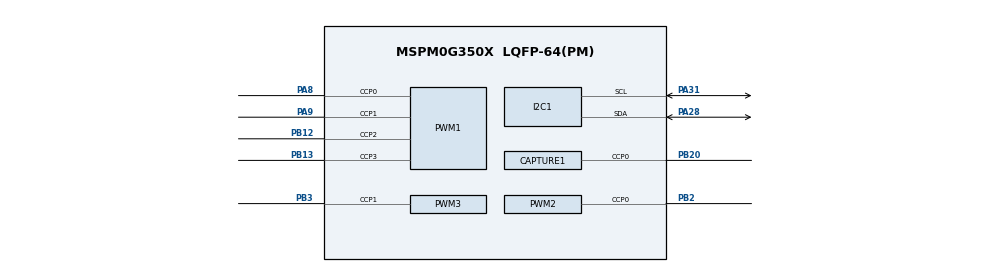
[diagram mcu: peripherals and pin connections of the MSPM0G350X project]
/**
 * @cliArgs --device "MSPM0G350X" --part "Default" --package "LQFP-64(PM)" --product "mspm0_sdk@2.02.00.05"
 * @versions {"tool":"1.21.1+3772"}
 */

/**
 * Import the modules used in this configuration.
 */
const CAPTURE  = scripting.addModule("/ti/driverlib/CAPTURE", {}, false);
const CAPTURE1 = CAPTURE.addInstance();
const GPIO     = scripting.addModule("/ti/driverlib/GPIO", {}, false);
const GPIO1    = GPIO.addInstance();
const GPIO2    = GPIO.addInstance();
const GPIO3    = GPIO.addInstance();
const GPIO4    = GPIO.addInstance();
const GPIO5    = GPIO.addInstance();
const GPIO6    = GPIO.addInstance();
const GPIO7    = GPIO.addInstance();
const GPIO8    = GPIO.addInstance();
const GPIO9    = GPIO.addInstance();
const GPIO10   = GPIO.addInstance();
const GPIO11   = GPIO.addInstance();
const GPIO12   = GPIO.addInstance();
const GPIO13   = GPIO.addInstance();
const GPIO14   = GPIO.addInstance();
const GPIO15   = GPIO.addInstance();
const GPIO16   = GPIO.addInstance();
const I2C      = scripting.addModule("/ti/driverlib/I2C", {}, false);
const I2C1     = I2C.addInstance();
const PWM      = scripting.addModule("/ti/driverlib/PWM", {}, false);
const PWM1     = PWM.addInstance();
const PWM2     = PWM.addInstance();
const PWM3     = PWM.addInstance();
const SYSCTL   = scripting.addModule("/ti/driverlib/SYSCTL");
const TIMER    = scripting.addModule("/ti/driverlib/TIMER", {}, false);
const TIMER1   = TIMER.addInstance();
const UART     = scripting.addModule("/ti/driverlib/UART", {}, false);
const UART1    = UART.addInstance();

/**
 * Write custom configuration values to the imported modules.
 */
CAPTURE1.$name                              = "ULTRASONIC_TIMER";
CAPTURE1.timerClkDiv                        = 8;
CAPTURE1.timerPeriod                        = "40ms";
CAPTURE1.peripheral.$assign                 = "TIMG12";
CAPTURE1.peripheral.ccp0Pin.$assign         = "PB20";
CAPTURE1.ccp0PinConfig.hideOutputInversion  = scripting.forceWrite(false);
CAPTURE1.ccp0PinConfig.onlyInternalResistor = scripting.forceWrite(false);
CAPTURE1.ccp0PinConfig.passedPeripheralType = scripting.forceWrite("Digital");
CAPTURE1.ccp0PinConfig.$name                = "ti_driverlib_gpio_GPIOPinGeneric8";

const Board = scripting.addModule("/ti/driverlib/Board", {}, false);

GPIO1.$name                          = "MOTORA_DIR";
GPIO1.associatedPins.create(2);
GPIO1.associatedPins[0].$name        = "MOTA_DIR1";
GPIO1.associatedPins[0].assignedPort = "PORTB";
GPIO1.associatedPins[0].assignedPin  = "15";
GPIO1.associatedPins[1].$name        = "MOTA_DIR2";
GPIO1.associatedPins[1].assignedPort = "PORTB";
GPIO1.associatedPins[1].assignedPin  = "16";

GPIO2.$name                          = "MOTORB_DIR";
GPIO2.associatedPins.create(2);
GPIO2.associatedPins[0].$name        = "MOTB_DIR1";
GPIO2.associatedPins[0].assignedPort = "PORTB";
GPIO2.associatedPins[0].assignedPin  = "5";
GPIO2.associatedPins[1].$name        = "MOTB_DIR2";
GPIO2.associatedPins[1].assignedPort = "PORTB";
GPIO2.associatedPins[1].assignedPin  = "4";

GPIO3.$name                          = "MOTORC_DIR";
GPIO3.associatedPins.create(2);
GPIO3.associatedPins[0].$name        = "MOTC_DIR1";
GPIO3.associatedPins[0].assignedPort = "PORTB";
GPIO3.associatedPins[0].assignedPin  = "9";
GPIO3.associatedPins[1].$name        = "MOTC_DIR2";
GPIO3.associatedPins[1].assignedPort = "PORTB";
GPIO3.associatedPins[1].assignedPin  = "7";

GPIO4.$name                          = "MOTORD_DIR";
GPIO4.associatedPins.create(2);
GPIO4.associatedPins[0].$name        = "MOTD_DIR1";
GPIO4.associatedPins[0].assignedPort = "PORTB";
GPIO4.associatedPins[0].assignedPin  = "26";
GPIO4.associatedPins[1].$name        = "MOTD_DIR2";
GPIO4.associatedPins[1].assignedPort = "PORTA";
GPIO4.associatedPins[1].assignedPin  = "13";

GPIO5.$name                          = "ENCA";
GPIO5.associatedPins.create(2);
GPIO5.associatedPins[0].$name        = "ENCA_A";
GPIO5.associatedPins[0].direction    = "INPUT";
GPIO5.associatedPins[0].assignedPort = "PORTB";
GPIO5.associatedPins[0].assignedPin  = "10";
GPIO5.associatedPins[0].interruptEn  = true;
GPIO5.associatedPins[0].polarity     = "FALL";
GPIO5.associatedPins[1].$name        = "ENCA_B";
GPIO5.associatedPins[1].direction    = "INPUT";
GPIO5.associatedPins[1].assignedPort = "PORTB";
GPIO5.associatedPins[1].assignedPin  = "11";
GPIO5.associatedPins[1].interruptEn  = true;
GPIO5.associatedPins[1].polarity     = "FALL";

GPIO6.$name                          = "ENCB";
GPIO6.associatedPins.create(2);
GPIO6.associatedPins[0].direction    = "INPUT";
GPIO6.associatedPins[0].$name        = "ENCB_A";
GPIO6.associatedPins[0].assignedPort = "PORTA";
GPIO6.associatedPins[0].assignedPin  = "29";
GPIO6.associatedPins[0].interruptEn  = true;
GPIO6.associatedPins[0].polarity     = "FALL";
GPIO6.associatedPins[1].direction    = "INPUT";
GPIO6.associatedPins[1].assignedPort = "PORTB";
GPIO6.associatedPins[1].$name        = "ENCB_b";
GPIO6.associatedPins[1].assignedPin  = "27";
GPIO6.associatedPins[1].interruptEn  = true;
GPIO6.associatedPins[1].polarity     = "FALL";

GPIO7.$name                          = "ENCC";
GPIO7.associatedPins.create(2);
GPIO7.associatedPins[0].direction    = "INPUT";
GPIO7.associatedPins[0].$name        = "ENCC_A";
GPIO7.associatedPins[0].assignedPort = "PORTA";
GPIO7.associatedPins[0].assignedPin  = "26";
GPIO7.associatedPins[0].interruptEn  = true;
GPIO7.associatedPins[0].polarity     = "FALL";
GPIO7.associatedPins[1].direction    = "INPUT";
GPIO7.associatedPins[1].$name        = "ENCC_B";
GPIO7.associatedPins[1].assignedPort = "PORTA";
GPIO7.associatedPins[1].assignedPin  = "27";
GPIO7.associatedPins[1].interruptEn  = true;
GPIO7.associatedPins[1].polarity     = "FALL";

GPIO8.$name                          = "ENCD";
GPIO8.associatedPins.create(2);
GPIO8.associatedPins[0].direction    = "INPUT";
GPIO8.associatedPins[0].assignedPort = "PORTB";
GPIO8.associatedPins[0].$name        = "ENCD_A";
GPIO8.associatedPins[0].assignedPin  = "21";
GPIO8.associatedPins[0].interruptEn  = true;
GPIO8.associatedPins[0].polarity     = "FALL";
GPIO8.associatedPins[1].direction    = "INPUT";
GPIO8.associatedPins[1].assignedPort = "PORTB";
GPIO8.associatedPins[1].$name        = "ENCD_B";
GPIO8.associatedPins[1].assignedPin  = "19";
GPIO8.associatedPins[1].interruptEn  = true;
GPIO8.associatedPins[1].polarity     = "FALL";

GPIO9.$name                          = "PTZ_DIR";
GPIO9.associatedPins.create(2);
GPIO9.associatedPins[0].$name        = "PTZ1_DIR";
GPIO9.associatedPins[0].assignedPort = "PORTA";
GPIO9.associatedPins[0].assignedPin  = "12";
GPIO9.associatedPins[1].$name        = "PTZ2_DIR";
GPIO9.associatedPins[1].assignedPort = "PORTB";
GPIO9.associatedPins[1].assignedPin  = "23";

GPIO10.$name                          = "ULTRASONIC";
GPIO10.associatedPins[0].$name        = "TRIG";
GPIO10.associatedPins[0].assignedPort = "PORTB";
GPIO10.associatedPins[0].assignedPin  = "25";

GPIO11.$name                          = "GRAY";
GPIO11.associatedPins.create(8);
GPIO11.associatedPins[0].$name        = "OUT1";
GPIO11.associatedPins[0].direction    = "INPUT";
GPIO11.associatedPins[0].assignedPort = "PORTA";
GPIO11.associatedPins[0].assignedPin  = "24";
GPIO11.associatedPins[1].$name        = "OUT2";
GPIO11.associatedPins[1].direction    = "INPUT";
GPIO11.associatedPins[1].assignedPort = "PORTA";
GPIO11.associatedPins[1].assignedPin  = "25";
GPIO11.associatedPins[2].$name        = "OUT3";
GPIO11.associatedPins[2].direction    = "INPUT";
GPIO11.associatedPins[2].assignedPort = "PORTB";
GPIO11.associatedPins[2].assignedPin  = "24";
GPIO11.associatedPins[3].$name        = "OUT4";
GPIO11.associatedPins[3].direction    = "INPUT";
GPIO11.associatedPins[3].assignedPort = "PORTA";
GPIO11.associatedPins[3].assignedPin  = "22";
GPIO11.associatedPins[4].$name        = "OUT5";
GPIO11.associatedPins[4].direction    = "INPUT";
GPIO11.associatedPins[4].assignedPort = "PORTA";
GPIO11.associatedPins[4].assignedPin  = "14";
GPIO11.associatedPins[5].$name        = "OUT6";
GPIO11.associatedPins[5].direction    = "INPUT";
GPIO11.associatedPins[5].assignedPort = "PORTA";
GPIO11.associatedPins[5].assignedPin  = "17";
GPIO11.associatedPins[6].$name        = "OUT7";
GPIO11.associatedPins[6].direction    = "INPUT";
GPIO11.associatedPins[6].assignedPort = "PORTB";
GPIO11.associatedPins[6].assignedPin  = "17";
GPIO11.associatedPins[7].$name        = "OUT8";
GPIO11.associatedPins[7].direction    = "INPUT";
GPIO11.associatedPins[7].assignedPort = "PORTB";
GPIO11.associatedPins[7].assignedPin  = "18";

GPIO12.$name                          = "KEY";
GPIO12.associatedPins.create(2);
GPIO12.associatedPins[0].$name        = "KEY1";
GPIO12.associatedPins[0].direction    = "INPUT";
GPIO12.associatedPins[0].assignedPort = "PORTA";
GPIO12.associatedPins[0].assignedPin  = "0";
GPIO12.associatedPins[0].interruptEn  = true;
GPIO12.associatedPins[0].polarity     = "FALL";
GPIO12.associatedPins[1].$name        = "KEY2";
GPIO12.associatedPins[1].direction    = "INPUT";
GPIO12.associatedPins[1].assignedPort = "PORTA";
GPIO12.associatedPins[1].assignedPin  = "1";
GPIO12.associatedPins[1].interruptEn  = true;
GPIO12.associatedPins[1].polarity     = "FALL";

GPIO13.$name                          = "LED12";
GPIO13.associatedPins.create(2);
GPIO13.associatedPins[0].$name        = "LED1_PIN";
GPIO13.associatedPins[0].assignedPort = "PORTB";
GPIO13.associatedPins[0].assignedPin  = "22";
GPIO13.associatedPins[0].initialValue = "SET";
GPIO13.associatedPins[1].$name        = "LED2_PIN";
GPIO13.associatedPins[1].assignedPort = "PORTA";
GPIO13.associatedPins[1].assignedPin  = "30";
GPIO13.associatedPins[1].initialValue = "SET";

GPIO14.$name                          = "LED34";
GPIO14.associatedPins.create(2);
GPIO14.associatedPins[0].$name        = "LED3_PIN";
GPIO14.associatedPins[0].assignedPort = "PORTB";
GPIO14.associatedPins[0].assignedPin  = "0";
GPIO14.associatedPins[0].initialValue = "SET";
GPIO14.associatedPins[1].$name        = "LED4_PIN";
GPIO14.associatedPins[1].assignedPort = "PORTB";
GPIO14.associatedPins[1].assignedPin  = "1";
GPIO14.associatedPins[1].initialValue = "SET";

GPIO15.$name                          = "BEEP_GPIO";
GPIO15.associatedPins[0].$name        = "BEEP_PIN";
GPIO15.associatedPins[0].assignedPort = "PORTA";
GPIO15.associatedPins[0].assignedPin  = "7";

GPIO16.$name                          = "OLED";
GPIO16.associatedPins.create(2);
GPIO16.associatedPins[0].$name        = "OLED_SDA";
GPIO16.associatedPins[0].assignedPort = "PORTA";
GPIO16.associatedPins[0].assignedPin  = "15";
GPIO16.associatedPins[1].$name        = "OLED_SCL";
GPIO16.associatedPins[1].assignedPort = "PORTA";
GPIO16.associatedPins[1].assignedPin  = "16";

I2C1.$name                     = "I2C_0";
I2C1.peripheral.sdaPin.$assign = "PA28";
I2C1.peripheral.sclPin.$assign = "PA31";
I2C1.sdaPinConfig.$name        = "ti_driverlib_gpio_GPIOPinGeneric5";
I2C1.sclPinConfig.$name        = "ti_driverlib_gpio_GPIOPinGeneric7";

PWM1.$name                              = "MOTOR_PWM";
PWM1.clockDivider                       = 8;
PWM1.ccIndex                            = [0,1,2,3];
PWM1.timerStartTimer                    = true;
PWM1.clockPrescale                      = 4;
PWM1.peripheral.ccp0Pin.$assign         = "PA8";
PWM1.peripheral.ccp1Pin.$assign         = "PA9";
PWM1.peripheral.ccp2Pin.$assign         = "PB12";
PWM1.peripheral.ccp3Pin.$assign         = "PB13";
PWM1.PWM_CHANNEL_0.$name                = "ti_driverlib_pwm_PWMTimerCC0";
PWM1.PWM_CHANNEL_1.$name                = "ti_driverlib_pwm_PWMTimerCC1";
PWM1.ccp0PinConfig.direction            = scripting.forceWrite("OUTPUT");
PWM1.ccp0PinConfig.hideOutputInversion  = scripting.forceWrite(false);
PWM1.ccp0PinConfig.onlyInternalResistor = scripting.forceWrite(false);
PWM1.ccp0PinConfig.passedPeripheralType = scripting.forceWrite("Digital");
PWM1.ccp0PinConfig.$name                = "ti_driverlib_gpio_GPIOPinGeneric0";
PWM1.ccp1PinConfig.direction            = scripting.forceWrite("OUTPUT");
PWM1.ccp1PinConfig.hideOutputInversion  = scripting.forceWrite(false);
PWM1.ccp1PinConfig.onlyInternalResistor = scripting.forceWrite(false);
PWM1.ccp1PinConfig.passedPeripheralType = scripting.forceWrite("Digital");
PWM1.ccp1PinConfig.$name                = "ti_driverlib_gpio_GPIOPinGeneric1";
PWM1.PWM_CHANNEL_2.$name                = "ti_driverlib_pwm_PWMTimerCC2";
PWM1.PWM_CHANNEL_3.$name                = "ti_driverlib_pwm_PWMTimerCC3";
PWM1.ccp2PinConfig.$name                = "ti_driverlib_gpio_GPIOPinGeneric2";
PWM1.ccp3PinConfig.$name                = "ti_driverlib_gpio_GPIOPinGeneric3";

PWM2.$name                              = "PTZ1_PWM";
PWM2.clockDivider                       = 8;
PWM2.clockPrescale                      = 100;
PWM2.ccIndex                            = [0];
PWM2.peripheral.ccp0Pin.$assign         = "PB2";
PWM2.PWM_CHANNEL_0.$name                = "ti_driverlib_pwm_PWMTimerCC4";
PWM2.PWM_CHANNEL_0.dutyCycle            = 50;
PWM2.ccp0PinConfig.direction            = scripting.forceWrite("OUTPUT");
PWM2.ccp0PinConfig.hideOutputInversion  = scripting.forceWrite(false);
PWM2.ccp0PinConfig.onlyInternalResistor = scripting.forceWrite(false);
PWM2.ccp0PinConfig.passedPeripheralType = scripting.forceWrite("Digital");
PWM2.ccp0PinConfig.$name                = "ti_driverlib_gpio_GPIOPinGeneric4";

PWM3.$name                              = "PTZ2_PWM";
PWM3.clockDivider                       = 8;
PWM3.clockPrescale                      = 100;
PWM3.ccIndex                            = [1];
PWM3.peripheral.$assign                 = "TIMG6";
PWM3.peripheral.ccp1Pin.$assign         = "PB3";
PWM3.ccp1PinConfig.direction            = scripting.forceWrite("OUTPUT");
PWM3.ccp1PinConfig.hideOutputInversion  = scripting.forceWrite(false);
PWM3.ccp1PinConfig.onlyInternalResistor = scripting.forceWrite(false);
PWM3.ccp1PinConfig.passedPeripheralType = scripting.forceWrite("Digital");
PWM3.ccp1PinConfig.$name                = "ti_driverlib_gpio_GPIOPinGeneric6";
PWM3.PWM_CHANNEL_1.$name                = "ti_driverlib_pwm_PWMTimerCC5";
PWM3.PWM_CHANNEL_1.dutyCycle            = 50;

SYSCTL.forceDefaultClkConfig = true;

TIMER1.$name              = "PID_TIMER";
TIMER1.timerClkDiv        = 8;
TIMER1.interrupts         = ["ZERO"];
TIMER1.timerClkPrescale   = 4;
TIMER1.timerPeriod        = "10ms";
TIMER1.peripheral.$assign = "TIMG7";

UART1.$name                            = "UART0";
UART1.enabledDMARXTriggers             = "DL_UART_DMA_INTERRUPT_RX";
UART1.enabledDMATXTriggers             = "DL_UART_DMA_INTERRUPT_TX";
UART1.enabledInterrupts                = ["DMA_DONE_RX","DMA_DONE_TX","RX_TIMEOUT_ERROR"];
UART1.txPinConfig.$name                = "ti_driverlib_gpio_GPIOPinGeneric9";
UART1.txPinConfig.direction            = scripting.forceWrite("OUTPUT");
UART1.txPinConfig.hideOutputInversion  = scripting.forceWrite(false);
UART1.txPinConfig.onlyInternalResistor = scripting.forceWrite(false);
UART1.txPinConfig.passedPeripheralType = scripting.forceWrite("Digital");
UART1.rxPinConfig.$name                = "ti_driverlib_gpio_GPIOPinGeneric10";
UART1.rxPinConfig.hideOutputInversion  = scripting.forceWrite(false);
UART1.rxPinConfig.onlyInternalResistor = scripting.forceWrite(false);
UART1.rxPinConfig.passedPeripheralType = scripting.forceWrite("Digital");
UART1.DMA_CHANNEL_RX.$name             = "DMA_CH0";
UART1.DMA_CHANNEL_TX.$name             = "DMA_CH1";

/**
 * Pinmux solution for unlocked pins/peripherals. This ensures that minor changes to the automatic solver in a future
 * version of the tool will not impact the pinmux you originally saw.  These lines can be completely deleted in order to
 * re-solve from scratch.
 */
Board.peripheral.$suggestSolution                = "DEBUGSS";
Board.peripheral.swclkPin.$suggestSolution       = "PA20";
Board.peripheral.swdioPin.$suggestSolution       = "PA19";
GPIO1.associatedPins[0].pin.$suggestSolution     = "PB15";
GPIO1.associatedPins[1].pin.$suggestSolution     = "PB16";
GPIO2.associatedPins[0].pin.$suggestSolution     = "PB5";
GPIO2.associatedPins[1].pin.$suggestSolution     = "PB4";
GPIO3.associatedPins[0].pin.$suggestSolution     = "PB9";
GPIO3.associatedPins[1].pin.$suggestSolution     = "PB7";
GPIO4.associatedPins[0].pin.$suggestSolution     = "PB26";
GPIO4.associatedPins[1].pin.$suggestSolution     = "PA13";
GPIO5.associatedPins[0].pin.$suggestSolution     = "PB10";
GPIO5.associatedPins[1].pin.$suggestSolution     = "PB11";
GPIO6.associatedPins[0].pin.$suggestSolution     = "PA29";
GPIO6.associatedPins[1].pin.$suggestSolution     = "PB27";
GPIO7.associatedPins[0].pin.$suggestSolution     = "PA26";
GPIO7.associatedPins[1].pin.$suggestSolution     = "PA27";
GPIO8.associatedPins[0].pin.$suggestSolution     = "PB21";
GPIO8.associatedPins[1].pin.$suggestSolution     = "PB19";
GPIO9.associatedPins[0].pin.$suggestSolution     = "PA12";
GPIO9.associatedPins[1].pin.$suggestSolution     = "PB23";
GPIO10.associatedPins[0].pin.$suggestSolution    = "PB25";
GPIO11.associatedPins[0].pin.$suggestSolution    = "PA24";
GPIO11.associatedPins[1].pin.$suggestSolution    = "PA25";
GPIO11.associatedPins[2].pin.$suggestSolution    = "PB24";
GPIO11.associatedPins[3].pin.$suggestSolution    = "PA22";
GPIO11.associatedPins[4].pin.$suggestSolution    = "PA14";
GPIO11.associatedPins[5].pin.$suggestSolution    = "PA17";
GPIO11.associatedPins[6].pin.$suggestSolution    = "PB17";
GPIO11.associatedPins[7].pin.$suggestSolution    = "PB18";
GPIO12.associatedPins[0].pin.$suggestSolution    = "PA0";
GPIO12.associatedPins[1].pin.$suggestSolution    = "PA1";
GPIO13.associatedPins[0].pin.$suggestSolution    = "PB22";
GPIO13.associatedPins[1].pin.$suggestSolution    = "PA30";
GPIO14.associatedPins[0].pin.$suggestSolution    = "PB0";
GPIO14.associatedPins[1].pin.$suggestSolution    = "PB1";
GPIO15.associatedPins[0].pin.$suggestSolution    = "PA7";
GPIO16.associatedPins[0].pin.$suggestSolution    = "PA15";
GPIO16.associatedPins[1].pin.$suggestSolution    = "PA16";
I2C1.peripheral.$suggestSolution                 = "I2C0";
PWM1.peripheral.$suggestSolution                 = "TIMA0";
PWM2.peripheral.$suggestSolution                 = "TIMA1";
SYSCTL.peripheral.$suggestSolution               = "SYSCTL";
UART1.peripheral.$suggestSolution                = "UART0";
UART1.peripheral.rxPin.$suggestSolution          = "PA11";
UART1.peripheral.txPin.$suggestSolution          = "PA10";
UART1.DMA_CHANNEL_RX.peripheral.$suggestSolution = "DMA_CH1";
UART1.DMA_CHANNEL_TX.peripheral.$suggestSolution = "DMA_CH0";
